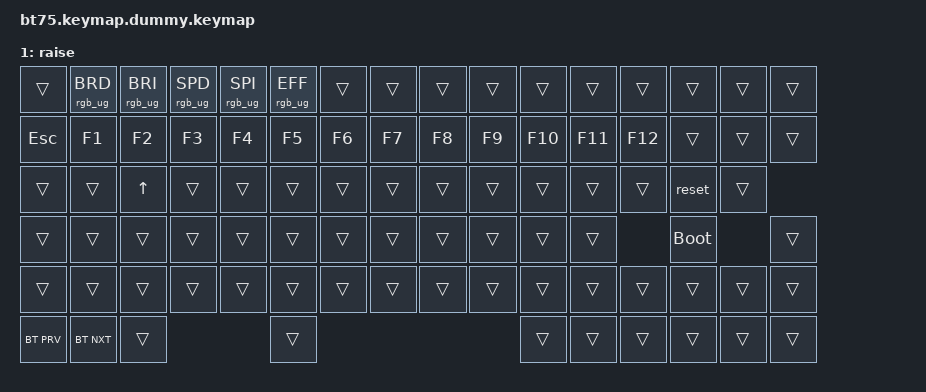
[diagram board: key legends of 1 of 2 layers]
/*
 * Copyright (c) 2020 The ZMK Contributors
 *
 * SPDX-License-Identifier: MIT
 */

#include <behaviors.dtsi>
#include <dt-bindings/zmk/keys.h>
#include <dt-bindings/zmk/bt.h>


&mt {
  //  flavor = "tap-preferred";
   // tapping_term_ms = <200>;
};

/ {
	keymap {
        compatible = "zmk,keymap";
       	default_layer {
			bindings = <
				&kp ESC		&kp C_BRIGHTNESS_DEC 	&kp C_BRIGHTNESS_INC 	&rgb_ug RGB_TOG 	&rgb_ug RGB_EFF 	&bl BL_DEC 	&bl BL_INC 	&kp C_PREV 	&kp C_PP 	&kp C_NEXT 	&none 			&none 				&kp HASH 				&kp C_AL_LOCK 	&kp C_MUTE 	&kp C_MUTE
				&kp GRAVE 	&kp N1 					&kp N2 					&kp N3 				&kp N4 				&kp N5 		&kp N6 		&kp N7 		&kp N8 		&kp N9 		&kp N0 			&de_eszett 			&kp EQUAL 				&kp BKSP 					&kp HOME
				&kp TAB		&kp Q 					&kp W 					&kp E 				&kp R 				&kp T 		&kp Y 		&kp U 		&kp I 		&kp O 		&kp P 			&de_ue 				&kp RBKT 				&kp BSLH					&kp INS
				&tog RAISE 	&kp A 					&kp S 					&kp D 				&kp F 				&kp G 		&kp H 		&kp J 		&kp K 		&kp L 		&de_oe 			&de_ae 						 				&kp RET						&kp PG_UP
				&kp LSHFT 				 			&kp Z 					&kp X 				&kp C 				&kp V 		&kp B 		&kp N 		&kp M 		&kp COMMA 	&kp DOT 		&kp SLASH			&kp HYPR 					&kp UP 		&kp PG_DN
				&kp LCTRL 	&kp LALT 				&kp LGUI 														&kp SPACE 													&kp RGUI 		&mo RAISE 			&kp MEH		&kp LEFT 		&kp DOWN 	&kp RIGHT
			>;
		};
		raise {
			bindings = <
				&trans		&rgb_ug RGB_BRD 		&rgb_ug RGB_BRI 		&rgb_ug RGB_SPD 	&rgb_ug RGB_SPI 	&rgb_ug RGB_EFF 	&trans 		&trans	&trans	&trans		&trans		&trans			&trans		&trans			&trans		&trans
				&kp ESC		&kp F1 					&kp F2 					&kp F3 				&kp F4 				&kp F5 				&kp F6 		&kp F7	&kp F8	&kp F9		&kp F10		&kp F11			&kp F12		&trans 			&trans		&trans
				&trans		&trans 					&kp UP 					&trans 				&trans 				&trans 				&trans 		&trans	&trans	&trans		&trans		&trans			&trans		&reset			&trans
				&trans		&trans 					&trans 					&trans 				&trans 				&trans 				&trans 		&trans	&trans	&trans		&trans		&trans						&bootloader					&trans
				&trans		&trans					&trans 					&trans 				&trans 				&trans 				&trans 		&trans	&trans	&trans		&trans		&trans			&trans 		&trans 			&trans 		&trans
				&bt BT_PRV 	&bt BT_NXT				&trans              											&trans														&trans		&trans			&trans		&trans			&trans		&trans
			>;
		};
	};
};
